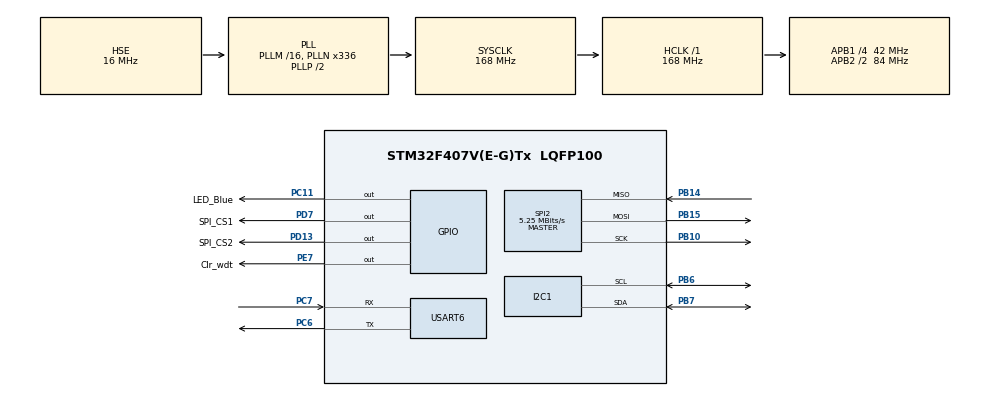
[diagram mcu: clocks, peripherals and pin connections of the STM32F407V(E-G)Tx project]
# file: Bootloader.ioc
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Dma.I2C1_RX.0.Direction=DMA_PERIPH_TO_MEMORY
Dma.I2C1_RX.0.FIFOMode=DMA_FIFOMODE_DISABLE
Dma.I2C1_RX.0.Instance=DMA1_Stream0
Dma.I2C1_RX.0.MemDataAlignment=DMA_MDATAALIGN_BYTE
Dma.I2C1_RX.0.MemInc=DMA_MINC_ENABLE
Dma.I2C1_RX.0.Mode=DMA_NORMAL
Dma.I2C1_RX.0.PeriphDataAlignment=DMA_PDATAALIGN_BYTE
Dma.I2C1_RX.0.PeriphInc=DMA_PINC_DISABLE
Dma.I2C1_RX.0.Priority=DMA_PRIORITY_LOW
Dma.I2C1_TX.1.Direction=DMA_MEMORY_TO_PERIPH
Dma.I2C1_TX.1.FIFOMode=DMA_FIFOMODE_DISABLE
Dma.I2C1_TX.1.Instance=DMA1_Stream6
Dma.I2C1_TX.1.MemDataAlignment=DMA_MDATAALIGN_BYTE
Dma.I2C1_TX.1.MemInc=DMA_MINC_ENABLE
Dma.I2C1_TX.1.Mode=DMA_NORMAL
Dma.I2C1_TX.1.PeriphDataAlignment=DMA_PDATAALIGN_BYTE
Dma.I2C1_TX.1.PeriphInc=DMA_PINC_DISABLE
Dma.I2C1_TX.1.Priority=DMA_PRIORITY_LOW
Dma.Request0=I2C1_RX
Dma.Request1=I2C1_TX
Mcu.Family=STM32F4
Mcu.Name=STM32F407V(E-G)Tx
Mcu.Package=LQFP100
NVIC.DMA1_Stream0_IRQn=true\:0\:0\:false\:false\:true\:false\:true\:true
NVIC.DMA1_Stream6_IRQn=true\:0\:0\:false\:false\:true\:false\:true\:true
NVIC.PriorityGroup=NVIC_PRIORITYGROUP_4
PA13.Mode=Serial_Wire
PA13.Signal=SYS_JTMS-SWDIO
PA14.Mode=Serial_Wire
PA14.Signal=SYS_JTCK-SWCLK
PB10.GPIO_Speed=GPIO_SPEED_FREQ_MEDIUM
PB10.Mode=Full_Duplex_Master
PB10.Signal=SPI2_SCK
PB14.GPIO_Speed=GPIO_SPEED_FREQ_MEDIUM
PB14.Mode=Full_Duplex_Master
PB14.Signal=SPI2_MISO
PB15.GPIO_Speed=GPIO_SPEED_FREQ_MEDIUM
PB15.Mode=Full_Duplex_Master
PB15.Signal=SPI2_MOSI
PB6.Mode=I2C
PB6.Signal=I2C1_SCL
PB7.Mode=I2C
PB7.Signal=I2C1_SDA
PC11.GPIO_Label=LED_Blue
PC11.PinState=GPIO_PIN_SET
PC11.Signal=GPIO_Output
PC6.Mode=Asynchronous
PC6.Signal=USART6_TX
PC7.Mode=Asynchronous
PC7.Signal=USART6_RX
PD13.GPIO_Label=SPI_CS2
PD13.PinState=GPIO_PIN_SET
PD13.Signal=GPIO_Output
PD7.GPIO_Label=SPI_CS1
PD7.PinState=GPIO_PIN_SET
PD7.Signal=GPIO_Output
PE7.GPIO_Label=Clr_wdt
PE7.Signal=GPIO_Output
PH0-OSC_IN.Mode=HSE-External-Oscillator
PH0-OSC_IN.Signal=RCC_OSC_IN
PH1-OSC_OUT.Mode=HSE-External-Oscillator
PH1-OSC_OUT.Signal=RCC_OSC_OUT
ProjectManager.HeapSize=0x200
ProjectManager.StackSize=0x800
ProjectManager.TargetToolchain=STM32CubeIDE
RCC.48MHZClocksFreq_Value=48000000
RCC.AHBFreq_Value=168000000
RCC.APB1CLKDivider=RCC_HCLK_DIV4
RCC.APB1Freq_Value=42000000
RCC.APB1TimFreq_Value=84000000
RCC.APB2CLKDivider=RCC_HCLK_DIV2
RCC.APB2Freq_Value=84000000
RCC.APB2TimFreq_Value=168000000
RCC.CortexFreq_Value=168000000
RCC.HCLKFreq_Value=168000000
RCC.HSE_VALUE=16000000
RCC.HSI_VALUE=16000000
RCC.LSE_VALUE=32768
RCC.PLLN=336
RCC.PLLQ=7
RCC.PLLSourceVirtual=RCC_PLLSOURCE_HSE
RCC.SYSCLKFreq_VALUE=168000000
RCC.SYSCLKSource=RCC_SYSCLKSOURCE_PLLCLK
RCC.VCOOutputFreq_Value=336000000
SPI2.BaudRatePrescaler=SPI_BAUDRATEPRESCALER_8
SPI2.CalculateBaudRate=5.25 MBits/s
SPI2.Direction=SPI_DIRECTION_2LINES
SPI2.Mode=SPI_MODE_MASTER
SPI2.VirtualType=VM_MASTER
USART6.VirtualMode=VM_ASYNC
board=custom

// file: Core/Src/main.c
/* USER CODE BEGIN Header */
/**
  ******************************************************************************
  * @file           : main.c
  * @brief          : SmartSwitch bootloader (Phase 5b). Minimal CubeMX init:
  *                   HSE + PLL, GPIO (PE7 WDT, PD7/PD13 flash CS, PC11 LED),
  *                   SPI2 (W25Q128) and USART6 (log), all polling. No I2C, RTC,
  *                   ADC or DMA: relay state and the RTC are never touched.
  *                   Boot logic: Core/Src/bl_main.c (docs/phase5b-bootloader.md).
  ******************************************************************************
  */
/* USER CODE END Header */
#include "main.h"

/* USER CODE BEGIN Includes */
#include "bl_main.h"
/* USER CODE END Includes */

I2C_HandleTypeDef hi2c1;
DMA_HandleTypeDef hdma_i2c1_rx;
DMA_HandleTypeDef hdma_i2c1_tx;

SPI_HandleTypeDef hspi2;

UART_HandleTypeDef huart6;

void SystemClock_Config(void);
static void MX_GPIO_Init(void);
static void MX_DMA_Init(void);
static void MX_USART6_UART_Init(void);
static void MX_SPI2_Init(void);
static void MX_I2C1_Init(void);

int main(void)
{

  /* USER CODE BEGIN 1 */
  /* Keep the external watchdog (STWD100, 1.12 s) fed from the first instructions. */
  Bl_EarlyWdtKick();
  /* USER CODE END 1 */

  /* MCU Configuration--------------------------------------------------------*/

  /* Reset of all peripherals, Initializes the Flash interface and the Systick. */
  HAL_Init();

  /* Configure the system clock */
  SystemClock_Config();

  /* Initialize all configured peripherals */
  MX_GPIO_Init();
  MX_DMA_Init();
  MX_USART6_UART_Init();
  MX_SPI2_Init();
  MX_I2C1_Init();
  /* USER CODE BEGIN 2 */
  Bl_Main();   /* never returns: jumps to the application or stays in rescue mode */
  /* USER CODE END 2 */

  /* Infinite loop */
  while (1)
  {

  }
}

void SystemClock_Config(void)
{
  RCC_OscInitTypeDef RCC_OscInitStruct = {0};
  RCC_ClkInitTypeDef RCC_ClkInitStruct = {0};

  /** Configure the main internal regulator output voltage
  */
  __HAL_RCC_PWR_CLK_ENABLE();
  __HAL_PWR_VOLTAGESCALING_CONFIG(PWR_REGULATOR_VOLTAGE_SCALE1);

  /** Initializes the RCC Oscillators according to the specified parameters
  * in the RCC_OscInitTypeDef structure.
  */
  RCC_OscInitStruct.OscillatorType = RCC_OSCILLATORTYPE_HSE;
  RCC_OscInitStruct.HSEState = RCC_HSE_ON;
  RCC_OscInitStruct.PLL.PLLState = RCC_PLL_ON;
  RCC_OscInitStruct.PLL.PLLSource = RCC_PLLSOURCE_HSE;
  RCC_OscInitStruct.PLL.PLLM = 16;
  RCC_OscInitStruct.PLL.PLLN = 336;
  RCC_OscInitStruct.PLL.PLLP = RCC_PLLP_DIV2;
  RCC_OscInitStruct.PLL.PLLQ = 7;
  if (HAL_RCC_OscConfig(&RCC_OscInitStruct) != HAL_OK)
  {
    Error_Handler();
  }

  /** Initializes the CPU, AHB and APB buses clocks
  */
  RCC_ClkInitStruct.ClockType = RCC_CLOCKTYPE_HCLK|RCC_CLOCKTYPE_SYSCLK
                              |RCC_CLOCKTYPE_PCLK1|RCC_CLOCKTYPE_PCLK2;
  RCC_ClkInitStruct.SYSCLKSource = RCC_SYSCLKSOURCE_PLLCLK;
  RCC_ClkInitStruct.AHBCLKDivider = RCC_SYSCLK_DIV1;
  RCC_ClkInitStruct.APB1CLKDivider = RCC_HCLK_DIV4;
  RCC_ClkInitStruct.APB2CLKDivider = RCC_HCLK_DIV2;

  if (HAL_RCC_ClockConfig(&RCC_ClkInitStruct, FLASH_LATENCY_5) != HAL_OK)
  {
    Error_Handler();
  }
}

static void MX_I2C1_Init(void)
{

  hi2c1.Instance = I2C1;
  hi2c1.Init.ClockSpeed = 100000;
  hi2c1.Init.DutyCycle = I2C_DUTYCYCLE_2;
  hi2c1.Init.OwnAddress1 = 0;
  hi2c1.Init.AddressingMode = I2C_ADDRESSINGMODE_7BIT;
  hi2c1.Init.DualAddressMode = I2C_DUALADDRESS_DISABLE;
  hi2c1.Init.OwnAddress2 = 0;
  hi2c1.Init.GeneralCallMode = I2C_GENERALCALL_DISABLE;
  hi2c1.Init.NoStretchMode = I2C_NOSTRETCH_DISABLE;
  if (HAL_I2C_Init(&hi2c1) != HAL_OK)
  {
    Error_Handler();
  }

}

static void MX_SPI2_Init(void)
{

  /* SPI2 parameter configuration*/
  hspi2.Instance = SPI2;
  hspi2.Init.Mode = SPI_MODE_MASTER;
  hspi2.Init.Direction = SPI_DIRECTION_2LINES;
  hspi2.Init.DataSize = SPI_DATASIZE_8BIT;
  hspi2.Init.CLKPolarity = SPI_POLARITY_LOW;
  hspi2.Init.CLKPhase = SPI_PHASE_1EDGE;
  hspi2.Init.NSS = SPI_NSS_SOFT;
  hspi2.Init.BaudRatePrescaler = SPI_BAUDRATEPRESCALER_8;
  hspi2.Init.FirstBit = SPI_FIRSTBIT_MSB;
  hspi2.Init.TIMode = SPI_TIMODE_DISABLE;
  hspi2.Init.CRCCalculation = SPI_CRCCALCULATION_DISABLE;
  hspi2.Init.CRCPolynomial = 10;
  if (HAL_SPI_Init(&hspi2) != HAL_OK)
  {
    Error_Handler();
  }

}

static void MX_USART6_UART_Init(void)
{

  huart6.Instance = USART6;
  huart6.Init.BaudRate = 115200;
  huart6.Init.WordLength = UART_WORDLENGTH_8B;
  huart6.Init.StopBits = UART_STOPBITS_1;
  huart6.Init.Parity = UART_PARITY_NONE;
  huart6.Init.Mode = UART_MODE_TX_RX;
  huart6.Init.HwFlowCtl = UART_HWCONTROL_NONE;
  huart6.Init.OverSampling = UART_OVERSAMPLING_16;
  if (HAL_UART_Init(&huart6) != HAL_OK)
  {
    Error_Handler();
  }

}

static void MX_DMA_Init(void)
{

  /* DMA controller clock enable */
  __HAL_RCC_DMA1_CLK_ENABLE();

  /* DMA interrupt init */
  /* DMA1_Stream0_IRQn interrupt configuration */
  HAL_NVIC_SetPriority(DMA1_Stream0_IRQn, 0, 0);
  HAL_NVIC_EnableIRQ(DMA1_Stream0_IRQn);
  /* DMA1_Stream6_IRQn interrupt configuration */
  HAL_NVIC_SetPriority(DMA1_Stream6_IRQn, 0, 0);
  HAL_NVIC_EnableIRQ(DMA1_Stream6_IRQn);

}

static void MX_GPIO_Init(void)
{
  GPIO_InitTypeDef GPIO_InitStruct = {0};

  /* GPIO Ports Clock Enable */
  __HAL_RCC_GPIOH_CLK_ENABLE();
  __HAL_RCC_GPIOE_CLK_ENABLE();
  __HAL_RCC_GPIOB_CLK_ENABLE();
  __HAL_RCC_GPIOD_CLK_ENABLE();
  __HAL_RCC_GPIOC_CLK_ENABLE();
  __HAL_RCC_GPIOA_CLK_ENABLE();

  /*Configure GPIO pin Output Level */
  HAL_GPIO_WritePin(Clr_wdt_GPIO_Port, Clr_wdt_Pin, GPIO_PIN_RESET);

  /*Configure GPIO pin Output Level */
  HAL_GPIO_WritePin(GPIOD, SPI_CS2_Pin|SPI_CS1_Pin, GPIO_PIN_SET);

  /*Configure GPIO pin Output Level */
  HAL_GPIO_WritePin(LED_Blue_GPIO_Port, LED_Blue_Pin, GPIO_PIN_SET);

  /*Configure GPIO pin : Clr_wdt_Pin */
  GPIO_InitStruct.Pin = Clr_wdt_Pin;
  GPIO_InitStruct.Mode = GPIO_MODE_OUTPUT_PP;
  GPIO_InitStruct.Pull = GPIO_NOPULL;
  GPIO_InitStruct.Speed = GPIO_SPEED_FREQ_LOW;
  HAL_GPIO_Init(Clr_wdt_GPIO_Port, &GPIO_InitStruct);

  /*Configure GPIO pins : SPI_CS2_Pin SPI_CS1_Pin */
  GPIO_InitStruct.Pin = SPI_CS2_Pin|SPI_CS1_Pin;
  GPIO_InitStruct.Mode = GPIO_MODE_OUTPUT_PP;
  GPIO_InitStruct.Pull = GPIO_NOPULL;
  GPIO_InitStruct.Speed = GPIO_SPEED_FREQ_LOW;
  HAL_GPIO_Init(GPIOD, &GPIO_InitStruct);

  /*Configure GPIO pin : LED_Blue_Pin */
  GPIO_InitStruct.Pin = LED_Blue_Pin;
  GPIO_InitStruct.Mode = GPIO_MODE_OUTPUT_PP;
  GPIO_InitStruct.Pull = GPIO_NOPULL;
  GPIO_InitStruct.Speed = GPIO_SPEED_FREQ_LOW;
  HAL_GPIO_Init(LED_Blue_GPIO_Port, &GPIO_InitStruct);

}

void Error_Handler(void)
{
  /* USER CODE BEGIN Error_Handler_Debug */
  /* Clock or peripheral init failed: stop here. The external watchdog resets the MCU
   * (with jumper DIS_WDT fitted the board stays halted). Relays are unaffected. */
  __disable_irq();
  while (1)
  {
  }
  /* USER CODE END Error_Handler_Debug */
}
